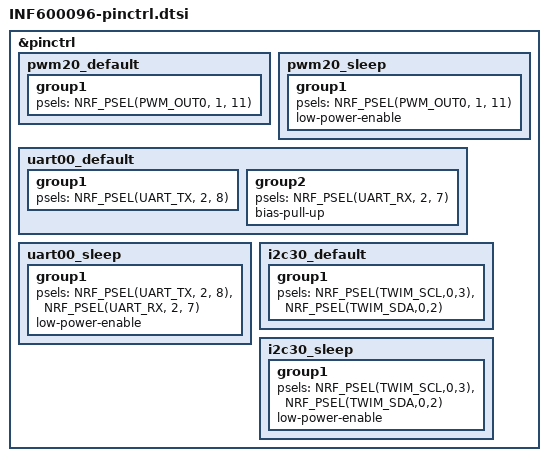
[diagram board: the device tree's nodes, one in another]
&pinctrl {
    pwm20_default: pwm20_default {
		group1 {
			psels = <NRF_PSEL(PWM_OUT0, 1, 11)>;
		};
	};

	pwm20_sleep: pwm20_sleep {
		group1 {
			psels = <NRF_PSEL(PWM_OUT0, 1, 11)>;
			low-power-enable;
		};
	};

	uart00_default: uart00_default {
		group1 {
			psels = <NRF_PSEL(UART_TX, 2, 8)>;
		};
		group2 {
			psels = <NRF_PSEL(UART_RX, 2, 7)>;
			bias-pull-up;
		};
	};

	uart00_sleep: uart00_sleep {
		group1 {
			psels = <NRF_PSEL(UART_TX, 2, 8)>,
				<NRF_PSEL(UART_RX, 2, 7)>;
			low-power-enable;
		};
	};

	i2c30_default: i2c30_default {
		group1 {
			psels = <NRF_PSEL(TWIM_SCL,0,3)>,
				<NRF_PSEL(TWIM_SDA,0,2)>;
		};
	};

	i2c30_sleep: i2c30_sleep {
		group1 {
			psels = <NRF_PSEL(TWIM_SCL,0,3)>,
				<NRF_PSEL(TWIM_SDA,0,2)>;
			low-power-enable;
		};
	};
};
